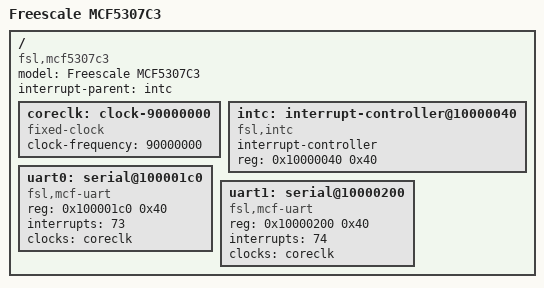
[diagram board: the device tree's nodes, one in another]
// SPDX-License-Identifier: GPL-2.0
/dts-v1/;

/ {
	model = "Freescale MCF5307C3";
	compatible = "fsl,mcf5307c3";
	#address-cells = <1>;
	#size-cells = <1>;
	interrupt-parent = <&intc>;

	coreclk: clock-90000000 {
		#clock-cells = <0>;
		compatible = "fixed-clock";
		clock-frequency = <90000000>;
	};

	intc: interrupt-controller@10000040 {
		compatible = "fsl,intc";
		interrupt-controller;
		#interrupt-cells = <1>;
		reg = <0x10000040 0x40>;
	};

	uart0: serial@100001c0 {
		compatible = "fsl,mcf-uart";
		reg = <0x100001c0 0x40>;
		interrupts = <73>;
		clocks = <&coreclk>;
	};

	uart1: serial@10000200 {
		compatible = "fsl,mcf-uart";
		reg = <0x10000200 0x40>;
		interrupts = <74>;
		clocks = <&coreclk>;
	};
};
